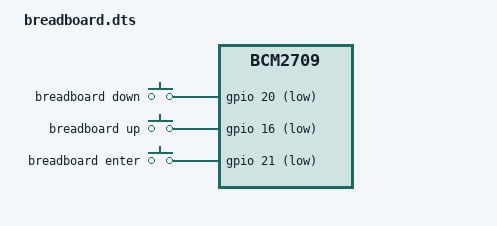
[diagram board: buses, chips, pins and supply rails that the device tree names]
 /dts-v1/;
    /plugin/;
    / {
       compatible = "brcm,bcm2835", "brcm,bcm2708", "brcm,bcm2709";
       
       fragment@0 {
          target-path = "/";
          __overlay__ {
             keypad: breadboard_keys {
                compatible = "gpio-keys";
                #address-cells = <1>;
                #size-cells = <0>;
		#autorepeat;
                button@20 {
                   label = "breadboard down";
                   linux,code = <108>;
                   gpios = <&gpio 20 1>;
                };
                button@16 {
                   label = "breadboard up";
                   linux,code = <103>;
                   gpios = <&gpio 16 1>;
                };
                button@21 {
                   label = "breadboard enter";
                   linux,code = <28>;
                   gpios = <&gpio 21 1>;
                };
             };
          };
       };
    };
